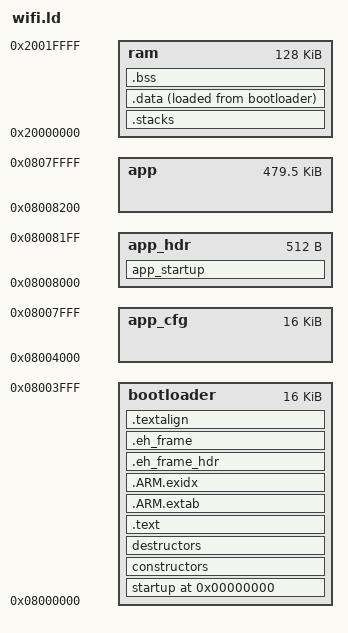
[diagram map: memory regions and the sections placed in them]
/*
    ChibiOS/RT - Copyright (C) 2006,2007,2008,2009,2010,
                 2011,2012 Giovanni Di Sirio.

    This file is part of ChibiOS/RT.

    ChibiOS/RT is free software; you can redistribute it and/or modify
    it under the terms of the GNU General Public License as published by
    the Free Software Foundation; either version 3 of the License, or
    (at your option) any later version.

    ChibiOS/RT is distributed in the hope that it will be useful,
    but WITHOUT ANY WARRANTY; without even the implied warranty of
    MERCHANTABILITY or FITNESS FOR A PARTICULAR PURPOSE.  See the
    GNU General Public License for more details.

    You should have received a copy of the GNU General Public License
    along with this program.  If not, see <http://www.gnu.org/licenses/>.

                                      ---

    A special exception to the GPL can be applied should you wish to distribute
    a combined work that includes ChibiOS/RT, without being obliged to provide
    the source code for any proprietary components. See the file exception.txt
    for full details of how and when the exception can be applied.
*/

/*
 * ST32F205xB memory setup.
 */
__main_stack_size__     = 0x0400;
__process_stack_size__  = 0x0400;

MEMORY
{
    bootloader : org = 0x08000000, len = 16k
    app_cfg    : org = 0x08004000, len = 16k
    app_hdr    : org = 0x08008000, len = 512
    app        : org = 0x08008200, len = 0x77E00 /* 479.5k */
    ram        : org = 0x20000000, len = 128k
}

__ram_start__           = ORIGIN(ram);
__ram_size__            = LENGTH(ram);
__ram_end__             = __ram_start__ + __ram_size__;

SECTIONS
{
    . = 0;
    _text = .;

    startup : ALIGN(16) SUBALIGN(16)
    {
        KEEP(*(vectors))
    } > bootloader

    app_startup : ALIGN(16) SUBALIGN(16)
    {
        PROVIDE(_app_hdr = .);
    } > app_hdr

    constructors : ALIGN(4) SUBALIGN(4)
    {
        PROVIDE(__init_array_start = .);
        KEEP(*(SORT(.init_array.*)))
        KEEP(*(.init_array))
        PROVIDE(__init_array_end = .);
    } > bootloader

    destructors : ALIGN(4) SUBALIGN(4)
    {
        PROVIDE(__fini_array_start = .);
        KEEP(*(.fini_array))
        KEEP(*(SORT(.fini_array.*)))
        PROVIDE(__fini_array_end = .);
    } > bootloader

    .text : ALIGN(16) SUBALIGN(16)
    {
        *(.text.startup.*)
        *(.text)
        *(.text.*)
        *(.rodata)
        *(.rodata.*)
        *(.glue_7t)
        *(.glue_7)
        *(.gcc*)
    } > bootloader

    .ARM.extab :
    {
        *(.ARM.extab* .gnu.linkonce.armextab.*)
    } > bootloader

    .ARM.exidx : {
        PROVIDE(__exidx_start = .);
        *(.ARM.exidx* .gnu.linkonce.armexidx.*)
        PROVIDE(__exidx_end = .);
     } > bootloader

    .eh_frame_hdr :
    {
        *(.eh_frame_hdr)
    } > bootloader

    .eh_frame : ONLY_IF_RO
    {
        *(.eh_frame)
    } > bootloader
    
    .textalign : ONLY_IF_RO
    {
        . = ALIGN(8);
    } > bootloader

    _etext = .;
    _textdata = _etext;

    .stacks :
    {
        . = ALIGN(8);
        __main_stack_base__ = .;
        . += __main_stack_size__;
        . = ALIGN(8);
        __main_stack_end__ = .;
        __process_stack_base__ = .;
        __main_thread_stack_base__ = .;
        . += __process_stack_size__;
        . = ALIGN(8);
        __process_stack_end__ = .;
        __main_thread_stack_end__ = .;
    } > ram

    .data :
    {
        . = ALIGN(4);
        PROVIDE(_data = .);
        *(.data)
        . = ALIGN(4);
        *(.data.*)
        . = ALIGN(4);
        *(.ramtext)
        . = ALIGN(4);
        PROVIDE(_edata = .);
    } > ram AT > bootloader

    .bss :
    {
        . = ALIGN(4);
        PROVIDE(_bss_start = .);
        *(.bss)
        . = ALIGN(4);
        *(.bss.*)
        . = ALIGN(4);
        *(COMMON)
        . = ALIGN(4);
        PROVIDE(_bss_end = .);
    } > ram    
}

PROVIDE(end = .);
_end            = .;

__heap_base__   = _end;
__heap_end__    = __ram_end__;
